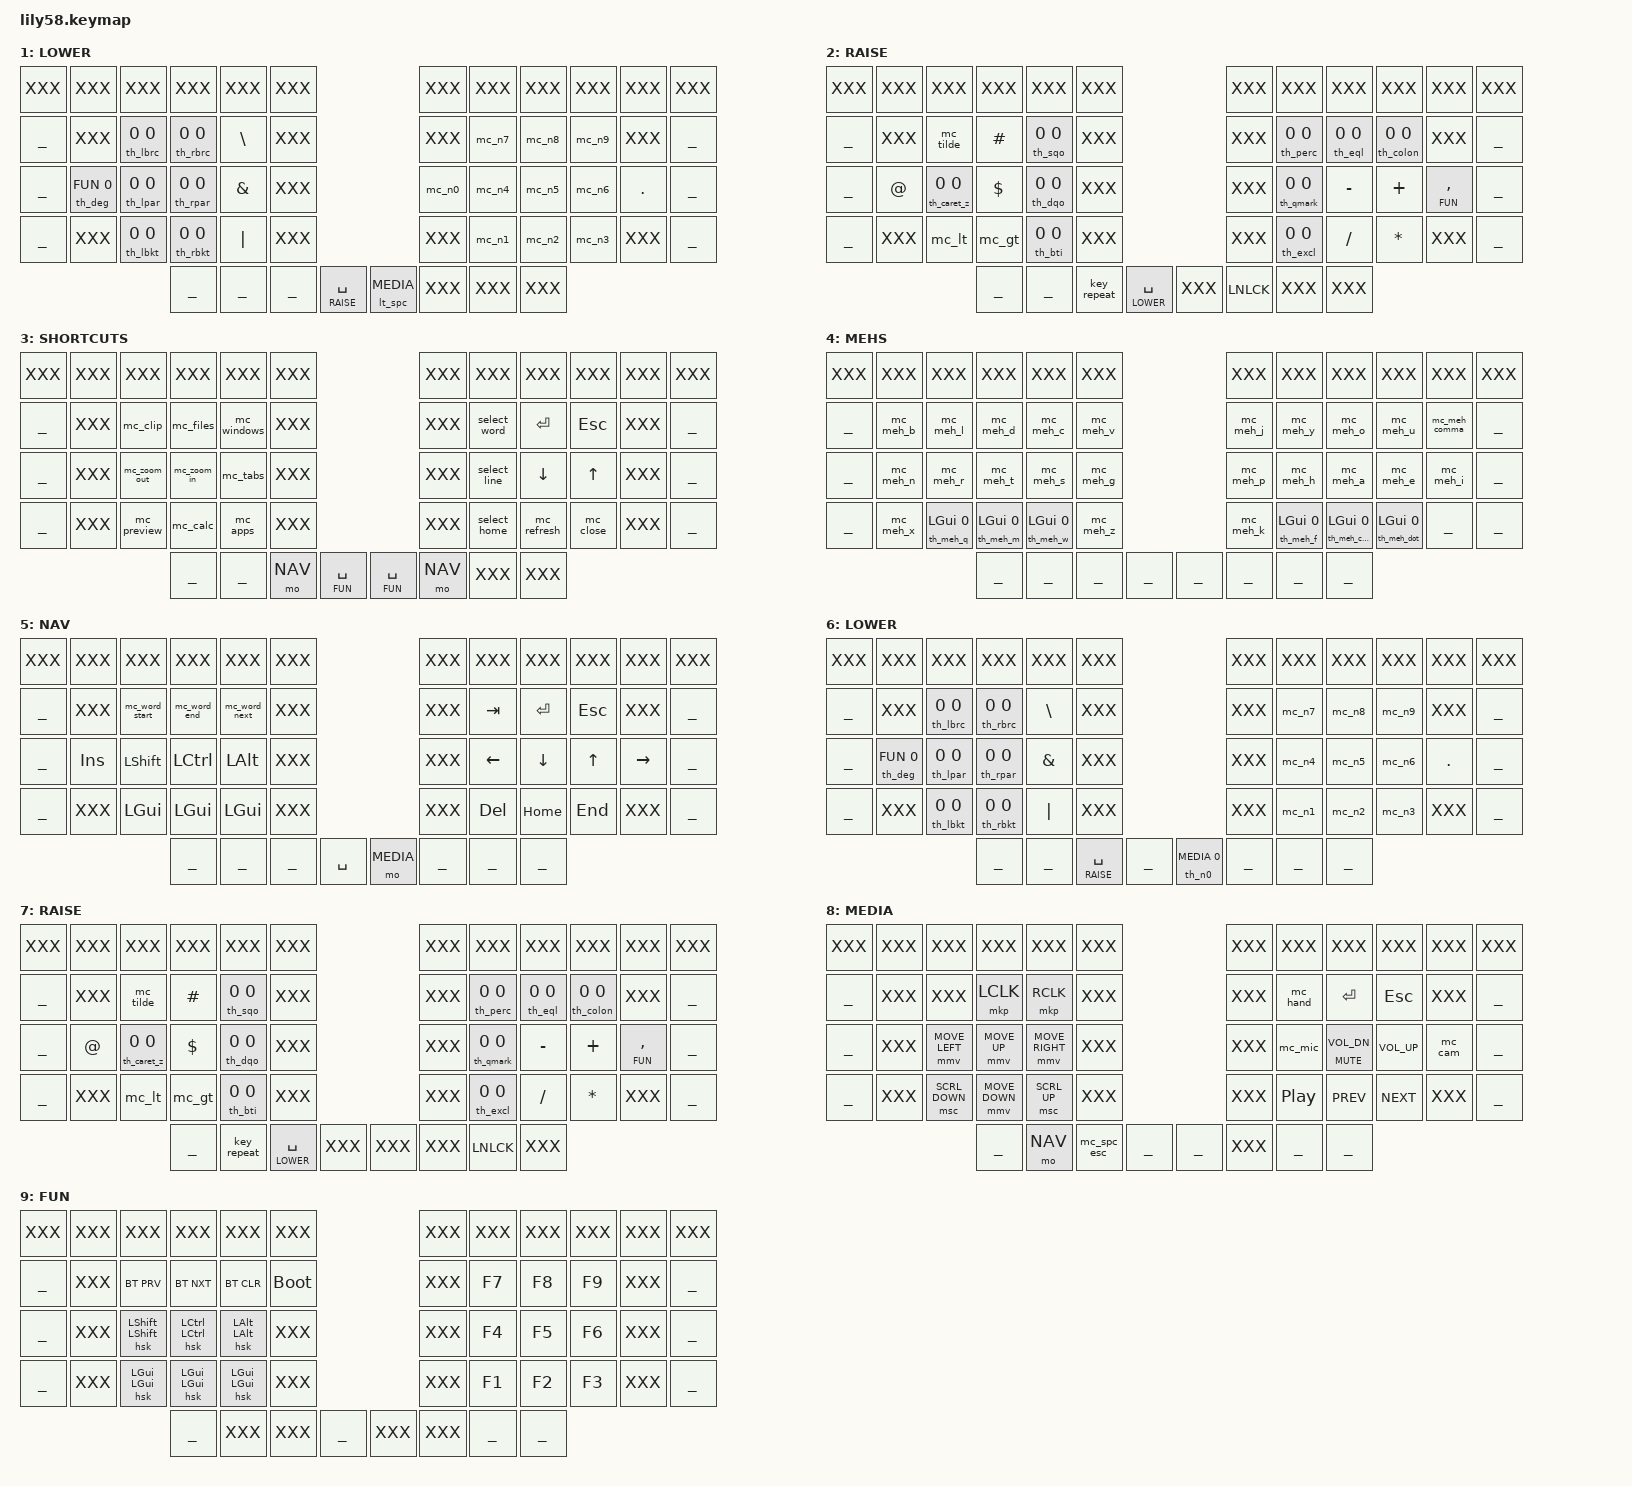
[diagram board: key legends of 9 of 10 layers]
#define CONFIG_WIRELESS
#include <behaviors.dtsi>
#include <dt-bindings/zmk/keys.h>
#include <dt-bindings/zmk/bt.h>


#include "definitions/config.dtsi"
#include "definitions/keycodes.h"

#include "zmk-helpers/helper.h"
#include "zmk-helpers/key-labels/lily58.h"

#include "features/homerow.dtsi"
#include "features/combos.dtsi"
#include "features/smart.dtsi"
// #include "features/leader.dtsi"
#include "features/mouse.dtsi"
#include "features/select.dtsi"
#include "features/symbols.dtsi"
#include "features/shortcuts.dtsi"
#include "features/magic.dtsi"


 /*                KEY POSITIONS
  ╭────────────────────────────┬────────────────────────────╮ ╭─────────────────────────────┬─────────────────────────────╮
  │  0   1   2   3   4   5     │      6   7   8   9  10  11 │ │ LT5 LT4 LT3 LT2 LT1 LT0     │     RT0 RT1 RT2 RT3 RT4 RT5 │
  │ 12  13  14  15  16  17     │     18  19  20  21  22  23 │ │ LM5 LM4 LM3 LM2 LM1 LM0     │     RM0 RM1 RM2 RM3 RM4 RM5 │
  │ 24  25  26  27  28  29     │     30  31  32  33  34  35 │ │ LB5 LB4 LB3 LB2 LB1 LB0     │     RB0 RB1 RB2 RB3 RB4 RB5 │
  │ 36  37  38  39  40  41  42 │ 43  44  45  46  47  48  49 │ │ LF5 LF4 LF3 LF2 LF1 LF0 LEC │ REC RF0 RF1 RF2 RF3 RF4 RF5 │
  ╰───────────╮ 50  51  52  53 │ 54  55  56  57 ╭───────────╯ ╰───────────╮ LH3 LH2 LH1 LH0 │ RH0 RH1 RH2 RH3 ╭───────────╯
              ╰────────────────┴────────────────╯                         ╰─────────────────┴─────────────────╯             */

/ {
  keymap {
    compatible = "zmk,keymap";
    default_layer {
      display-name = "ALPHA1";
      bindings = <

//╭───────────────────┬───────────────────┬───────────────────┬───────────────────┬───────────────────┬───────────────────╮                                         ╭───────────────────┬───────────────────┬───────────────────┬───────────────────┬───────────────────┬───────────────────╮
   XXX                 &kp N1              &kp N2              &kp N3              &kp N4              &kp N5                                                        &kp N6              &kp N7              &kp N8              &kp N9              &kp N0              XXX              
//├───────────────────┼───────────────────┼───────────────────┼───────────────────┼───────────────────┼───────────────────┤                                         ├───────────────────┼───────────────────┼───────────────────┼───────────────────┼───────────────────┼───────────────────┤
   XXX                 &kp B               &kp L               &hml LMEH D         &hml LHYP C         &kp V                                                         &kp J               &hmr RHYP Y         &hmr RMEH O         &kp U               &kp SQT             XXX
//├───────────────────┼───────────────────┼───────────────────┼───────────────────┼───────────────────┼───────────────────┤                                         ├───────────────────┼───────────────────┼───────────────────┼───────────────────┼───────────────────┼───────────────────┤
   XXX                 &lt SHORTCUTS N     &hml LSHFT R        &hml LCTRL T        &hml LALT S         &kp G                                                         &kp P               &hmr RALT H         &hmr RCTRL A        &hmr RSHFT E        &lt SHORTCUTS I     XXX
//├───────────────────┼───────────────────┼───────────────────┼───────────────────┼───────────────────┼───────────────────┼───────────────────╮ ╭───────────────────├───────────────────├───────────────────┼───────────────────┼───────────────────┼───────────────────┼───────────────────┤
   XXX                 &kp X               &hml LGUI Q         &hml LGUI M         &hml LGUI W         &kp Z               XXX                   XXX                 &kp K               &hmr RGUI F         &mm_comma           &mm_dot             &mm_qexcl           XXX
//╰───────────────────┴───────────────────┴───────────────────┴───────────────────┼───────────────────┼───────────────────┼───────────────────┤ ├───────────────────┼───────────────────┼───────────────────┴───────────────────┴───────────────────┴───────────────────┴───────────────────╯
                                                               XXX                 &key_repeat         &lt NAV BSPC        &lt LOW_CP ESC        &lt RAISE RET       &lt MEDIA SPACE     &key_repeat         XXX
//                                                            ╰───────────────────┴───────────────────┴───────────────────┴───────────────────╯ ╰───────────────────┴───────────────────┴───────────────────┴───────────────────╯
          >;
    };

    lower_layer {
         display-name = "LOWER";
         bindings = <
//╭───────────────────┬───────────────────┬───────────────────┬───────────────────┬───────────────────┬───────────────────╮                                         ╭───────────────────┬───────────────────┬───────────────────┬───────────────────┬───────────────────┬───────────────────╮
   XXX                 XXX                 XXX                 XXX                 XXX                 XXX                                                           XXX                 XXX                 XXX                 XXX                 XXX                 XXX                 
//├───────────────────┼───────────────────┼───────────────────┼───────────────────┼───────────────────┼───────────────────┤                                         ├───────────────────┼───────────────────┼───────────────────┼───────────────────┼───────────────────┼───────────────────┤
   ___                 XXX                 &th_lbrc 0 0        &th_rbrc 0 0        &kp BSLH            XXX                                                           XXX                 &mc_n7              &mc_n8              &mc_n9              XXX                 ___
//├───────────────────┼───────────────────┼───────────────────┼───────────────────┼───────────────────┼───────────────────┤                                         ├───────────────────┼───────────────────┼───────────────────┼───────────────────┼───────────────────┼───────────────────┤
   ___                 &th_deg FUN 0       &th_lpar 0 0        &th_rpar 0 0        &kp AMPS            XXX                                                           &mc_n0              &mc_n4              &mc_n5              &mc_n6              &kp DOT             ___
//├───────────────────┼───────────────────┼───────────────────┼───────────────────┼───────────────────┼───────────────────┤                                         ├───────────────────┼───────────────────┼───────────────────┼───────────────────┼───────────────────┼───────────────────┤
   ___                 XXX                 &th_lbkt 0 0        &th_rbkt 0 0        &kp PIPE            XXX                                                           XXX                 &mc_n1              &mc_n2              &mc_n3              XXX                 ___
//╰───────────────────┴───────────────────┴───────────────────┴───────────────────┼───────────────────┼───────────────────┼───────────────────┤ ├───────────────────┼───────────────────┼───────────────────┴───────────────────┴───────────────────┴───────────────────┴───────────────────╯
                                                               ___                 ___                 ___                 &lt RAISE SPACE       &lt_spc MEDIA       XXX                 XXX                 XXX
//                                                            ╰───────────────────┴───────────────────┴───────────────────┴───────────────────╯ ╰───────────────────┴───────────────────┴───────────────────┴───────────────────╯
               >;
    };
    raise_layer {
         display-name = "RAISE";
         bindings = <
//╭───────────────────┬───────────────────┬───────────────────┬───────────────────┬───────────────────┬───────────────────╮                                         ╭───────────────────┬───────────────────┬───────────────────┬───────────────────┬───────────────────┬───────────────────╮
   XXX                 XXX                 XXX                 XXX                 XXX                 XXX                                                           XXX                 XXX                 XXX                 XXX                 XXX                 XXX                 
//├───────────────────┼───────────────────┼───────────────────┼───────────────────┼───────────────────┼───────────────────┤                                         ├───────────────────┼───────────────────┼───────────────────┼───────────────────┼───────────────────┼───────────────────┤
   ___                 XXX                 &mc_tilde           &kp HASH            &th_sqo 0 0         XXX                                                           XXX                 &th_perc 0 0        &th_eql 0 0         &th_colon 0 0       XXX                 ___
//├───────────────────┼───────────────────┼───────────────────┼───────────────────┼───────────────────┼───────────────────┤                                         ├───────────────────┼───────────────────┼───────────────────┼───────────────────┼───────────────────┼───────────────────┤
   ___                 &kp AT              &th_caret_z 0 0     &kp DOLLAR          &th_dqo 0 0         XXX                                                           XXX                 &th_qmark 0 0       &kp MINUS           &kp PLUS            &lt FUN COMMA       ___
//├───────────────────┼───────────────────┼───────────────────┼───────────────────┼───────────────────┼───────────────────┤                                         ├───────────────────┼───────────────────┼───────────────────┼───────────────────┼───────────────────┼───────────────────┤
   ___                 XXX                 &mc_lt              &mc_gt              &th_bti 0 0         XXX                                                           XXX                 &th_excl 0 0        &kp SLASH           &kp STAR            XXX                 ___
//╰───────────────────┴───────────────────┴───────────────────┴───────────────────┼───────────────────┼───────────────────┼───────────────────┤ ├───────────────────┼───────────────────┼───────────────────┴───────────────────┴───────────────────┴───────────────────┴───────────────────╯
                                                               ___                 ___                 &key_repeat         &lt LOWER SPACE       XXX                 &kp LNLCK           XXX                 XXX
//                                                            ╰───────────────────┴───────────────────┴───────────────────┴───────────────────╯ ╰───────────────────┴───────────────────┴───────────────────┴───────────────────╯
               >;
    };

    shortcuts_layer {
      display-name = "SHORTCUTS";
      bindings = <

//╭───────────────────┬───────────────────┬───────────────────┬───────────────────┬───────────────────┬───────────────────╮                                         ╭───────────────────┬───────────────────┬───────────────────┬───────────────────┬───────────────────┬───────────────────╮
   XXX                 XXX                 XXX                 XXX                 XXX                 XXX                                                           XXX                 XXX                 XXX                 XXX                 XXX                 XXX                 
//├───────────────────┼───────────────────┼───────────────────┼───────────────────┼───────────────────┼───────────────────┤                                         ├───────────────────┼───────────────────┼───────────────────┼───────────────────┼───────────────────┼───────────────────┤
   ___                 XXX                 &mc_clip            &mc_files           &mc_windows         XXX                                                           XXX                 &select_word        &kp ENTER           &kp ESC             XXX                 ___
//├───────────────────┼───────────────────┼───────────────────┼───────────────────┼───────────────────┼───────────────────┤                                         ├───────────────────┼───────────────────┼───────────────────┼───────────────────┼───────────────────┼───────────────────┤
   ___                 XXX                 &mc_zoom_out        &mc_zoom_in         &mc_tabs            XXX                                                           XXX                 &select_line        &kp DOWN            &kp UP              XXX                 ___
//├───────────────────┼───────────────────┼───────────────────┼───────────────────┼───────────────────┼───────────────────┤                                         ├───────────────────┼───────────────────┼───────────────────┼───────────────────┼───────────────────┼───────────────────┤
   ___                 XXX                 &mc_preview         &mc_calc            &mc_apps            XXX                                                           XXX                 &select_home        &mc_refresh         &mc_close           XXX                 ___
//╰───────────────────┴───────────────────┴───────────────────┴───────────────────┼───────────────────┼───────────────────┼───────────────────┤ ├───────────────────┼───────────────────┼───────────────────┴───────────────────┴───────────────────┴───────────────────┴───────────────────╯
                                                               ___                 ___                 &mo NAV             &lt FUN SPACE         &lt FUN SPACE       &mo NAV             XXX                 XXX
//                                                            ╰───────────────────┴───────────────────┴───────────────────┴───────────────────╯ ╰───────────────────┴───────────────────┴───────────────────┴───────────────────╯
               >;
    };

    mehs_layer {
         display-name = "MEHS";
         bindings = <
//╭───────────────────┬───────────────────┬───────────────────┬───────────────────┬───────────────────┬───────────────────╮                                         ╭───────────────────┬───────────────────┬───────────────────┬───────────────────┬───────────────────┬───────────────────╮
   XXX                 XXX                 XXX                 XXX                 XXX                 XXX                                                           XXX                 XXX                 XXX                 XXX                 XXX                 XXX                 
//├───────────────────┼───────────────────┼───────────────────┼───────────────────┼───────────────────┼───────────────────┤                                         ├───────────────────┼───────────────────┼───────────────────┼───────────────────┼───────────────────┼───────────────────┤
   ___                 &mc_meh_b           &mc_meh_l           &mc_meh_d           &mc_meh_c           &mc_meh_v                                                     &mc_meh_j           &mc_meh_y           &mc_meh_o           &mc_meh_u           &mc_meh_comma        ___
//├───────────────────┼───────────────────┼───────────────────┼───────────────────┼───────────────────┼───────────────────┤                                         ├───────────────────┼───────────────────┼───────────────────┼───────────────────┼───────────────────┼───────────────────┤
   ___                 &mc_meh_n           &mc_meh_r           &mc_meh_t           &mc_meh_s           &mc_meh_g                                                     &mc_meh_p           &mc_meh_h           &mc_meh_a           &mc_meh_e           &mc_meh_i           ___
//├───────────────────┼───────────────────┼───────────────────┼───────────────────┼───────────────────┼───────────────────┤                                         ├───────────────────┼───────────────────┼───────────────────┼───────────────────┼───────────────────┼───────────────────┤
   ___                 &mc_meh_x           &th_meh_q LGUI 0    &th_meh_m LGUI 0    &th_meh_w LGUI 0    &mc_meh_z                                                     &mc_meh_k           &th_meh_f LGUI 0    &th_meh_comm LGUI 0 &th_meh_dot LGUI 0  ___                 ___
//╰───────────────────┴───────────────────┴───────────────────┴───────────────────┼───────────────────┼───────────────────┼───────────────────┤ ├───────────────────┼───────────────────┼───────────────────┴───────────────────┴───────────────────┴───────────────────┴───────────────────╯
                                                               ___                 ___                 ___                 ___                   ___                 ___                 ___                 ___
//                                                            ╰───────────────────┴───────────────────┴───────────────────┴───────────────────╯ ╰───────────────────┴───────────────────┴───────────────────┴───────────────────╯
          >;
    };

    navigation_layer {
         display-name = "NAV";
         bindings = <

//╭───────────────────┬───────────────────┬───────────────────┬───────────────────┬───────────────────┬───────────────────╮                                         ╭───────────────────┬───────────────────┬───────────────────┬───────────────────┬───────────────────┬───────────────────╮
   XXX                 XXX                 XXX                 XXX                 XXX                 XXX                                                           XXX                 XXX                 XXX                 XXX                 XXX                 XXX                 
//├───────────────────┼───────────────────┼───────────────────┼───────────────────┼───────────────────┼───────────────────┤                                         ├───────────────────┼───────────────────┼───────────────────┼───────────────────┼───────────────────┼───────────────────┤
   ___                 XXX                 &mc_word_start      &mc_word_end        &mc_word_next       XXX                                                           XXX                 &kp TAB             &kp ENTER           &kp ESC             XXX                 ___
//├───────────────────┼───────────────────┼───────────────────┼───────────────────┼───────────────────┼───────────────────┤                                         ├───────────────────┼───────────────────┼───────────────────┼───────────────────┼───────────────────┼───────────────────┤
   ___                 &kp INS             &kp LSHFT           &kp LCTRL           &kp LALT            XXX                                                           XXX                 &kp LEFT            &kp DOWN            &kp UP              &kp RIGHT           ___
//├───────────────────┼───────────────────┼───────────────────┼───────────────────┼───────────────────┼───────────────────┤                                         ├───────────────────┼───────────────────┼───────────────────┼───────────────────┼───────────────────┼───────────────────┤
   ___                 XXX                 &kp LGUI            &kp LGUI            &kp LGUI            XXX                                                           XXX                 &kp DEL             &kp HOME            &kp END             XXX                 ___
//╰───────────────────┴───────────────────┴───────────────────┴───────────────────┼───────────────────┼───────────────────┼───────────────────┤ ├───────────────────┼───────────────────┼───────────────────┴───────────────────┴───────────────────┴───────────────────┴───────────────────╯
                                                               ___                 ___                 ___                 &kp SPACE             &mo MEDIA           ___                 ___                 ___
//                                                            ╰───────────────────┴───────────────────┴───────────────────┴───────────────────╯ ╰───────────────────┴───────────────────┴───────────────────┴───────────────────╯
          >;
    };
    lower_copy_layer {
         display-name = "LOWER";
         bindings = <
//╭───────────────────┬───────────────────┬───────────────────┬───────────────────┬───────────────────┬───────────────────╮                                         ╭───────────────────┬───────────────────┬───────────────────┬───────────────────┬───────────────────┬───────────────────╮
   XXX                 XXX                 XXX                 XXX                 XXX                 XXX                                                           XXX                 XXX                 XXX                 XXX                 XXX                 XXX                 
//├───────────────────┼───────────────────┼───────────────────┼───────────────────┼───────────────────┼───────────────────┤                                         ├───────────────────┼───────────────────┼───────────────────┼───────────────────┼───────────────────┼───────────────────┤
   ___                 XXX                 &th_lbrc 0 0        &th_rbrc 0 0        &kp BSLH            XXX                                                           XXX                 &mc_n7              &mc_n8              &mc_n9              XXX                 ___
//├───────────────────┼───────────────────┼───────────────────┼───────────────────┼───────────────────┼───────────────────┤                                         ├───────────────────┼───────────────────┼───────────────────┼───────────────────┼───────────────────┼───────────────────┤
   ___                 &th_deg FUN 0       &th_lpar 0 0        &th_rpar 0 0        &kp AMPS            XXX                                                           XXX                 &mc_n4              &mc_n5              &mc_n6              &kp DOT             ___
//├───────────────────┼───────────────────┼───────────────────┼───────────────────┼───────────────────┼───────────────────┤                                         ├───────────────────┼───────────────────┼───────────────────┼───────────────────┼───────────────────┼───────────────────┤
   ___                 XXX                 &th_lbkt 0 0        &th_rbkt 0 0        &kp PIPE            XXX                                                           XXX                 &mc_n1              &mc_n2              &mc_n3              XXX                 ___
//╰───────────────────┴───────────────────┴───────────────────┴───────────────────┼───────────────────┼───────────────────┼───────────────────┤ ├───────────────────┼───────────────────┼───────────────────┴───────────────────┴───────────────────┴───────────────────┴───────────────────╯
                                                               ___                 ___                 &lt RAISE SPACE     ___                   &th_n0 MEDIA 0      ___                 ___                 ___
//                                                            ╰───────────────────┴───────────────────┴───────────────────┴───────────────────╯ ╰───────────────────┴───────────────────┴───────────────────┴───────────────────╯
               >;
    };
    raise_copy_layer {
         display-name = "RAISE";
         bindings = <
//╭───────────────────┬───────────────────┬───────────────────┬───────────────────┬───────────────────┬───────────────────╮                                         ╭───────────────────┬───────────────────┬───────────────────┬───────────────────┬───────────────────┬───────────────────╮
   XXX                 XXX                 XXX                 XXX                 XXX                 XXX                                                           XXX                 XXX                 XXX                 XXX                 XXX                 XXX                 
//├───────────────────┼───────────────────┼───────────────────┼───────────────────┼───────────────────┼───────────────────┤                                         ├───────────────────┼───────────────────┼───────────────────┼───────────────────┼───────────────────┼───────────────────┤
   ___                 XXX                 &mc_tilde           &kp HASH            &th_sqo 0 0         XXX                                                           XXX                 &th_perc 0 0        &th_eql 0 0         &th_colon 0 0       XXX                 ___
//├───────────────────┼───────────────────┼───────────────────┼───────────────────┼───────────────────┼───────────────────┤                                         ├───────────────────┼───────────────────┼───────────────────┼───────────────────┼───────────────────┼───────────────────┤
   ___                 &kp AT              &th_caret_z 0 0     &kp DOLLAR          &th_dqo 0 0         XXX                                                           XXX                 &th_qmark 0 0       &kp MINUS           &kp PLUS            &lt FUN COMMA       ___
//├───────────────────┼───────────────────┼───────────────────┼───────────────────┼───────────────────┼───────────────────┤                                         ├───────────────────┼───────────────────┼───────────────────┼───────────────────┼───────────────────┼───────────────────┤
   ___                 XXX                 &mc_lt              &mc_gt              &th_bti 0 0         XXX                                                           XXX                 &th_excl 0 0        &kp SLASH           &kp STAR            XXX                 ___
//╰───────────────────┴───────────────────┴───────────────────┴───────────────────┼───────────────────┼───────────────────┼───────────────────┤ ├───────────────────┼───────────────────┼───────────────────┴───────────────────┴───────────────────┴───────────────────┴───────────────────╯
                                                               ___                 &key_repeat         &lt LOWER SPACE     XXX                   XXX                 XXX                 &kp LNLCK           XXX
//                                                            ╰───────────────────┴───────────────────┴───────────────────┴───────────────────╯ ╰───────────────────┴───────────────────┴───────────────────┴───────────────────╯
               >;
    };

    media_layer {
        display-name = "MEDIA";
        bindings = <

//╭───────────────────┬───────────────────┬───────────────────┬───────────────────┬───────────────────┬───────────────────╮                                         ╭───────────────────┬───────────────────┬───────────────────┬───────────────────┬───────────────────┬───────────────────╮
   XXX                 XXX                 XXX                 XXX                 XXX                 XXX                                                           XXX                 XXX                 XXX                 XXX                 XXX                 XXX                 
//├───────────────────┼───────────────────┼───────────────────┼───────────────────┼───────────────────┼───────────────────┤                                         ├───────────────────┼───────────────────┼───────────────────┼───────────────────┼───────────────────┼───────────────────┤
   ___                 XXX                 XXX                 &mkp LCLK           &mkp RCLK           XXX                                                           XXX                 &mc_hand            &kp ENTER           &kp ESC             XXX                 ___
//├───────────────────┼───────────────────┼───────────────────┼───────────────────┼───────────────────┼───────────────────┤                                         ├───────────────────┼───────────────────┼───────────────────┼───────────────────┼───────────────────┼───────────────────┤
   ___                 XXX                 &mmv MOVE_LEFT      &mmv MOVE_UP        &mmv MOVE_RIGHT     XXX                                                           XXX                 &mc_mic             &mt C_MUTE C_VOL_DN &kp C_VOL_UP        &mc_cam             ___
//├───────────────────┼───────────────────┼───────────────────┼───────────────────┼───────────────────┼───────────────────┤                                         ├───────────────────┼───────────────────┼───────────────────┼───────────────────┼───────────────────┼───────────────────┤
   ___                 XXX                 &msc SCRL_DOWN      &mmv MOVE_DOWN      &msc SCRL_UP        XXX                                                           XXX                 &kp C_PP            &kp C_PREV          &kp C_NEXT          XXX                 ___
//╰───────────────────┴───────────────────┴───────────────────┴───────────────────┼───────────────────┼───────────────────┼───────────────────┤ ├───────────────────┼───────────────────┼───────────────────┴───────────────────┴───────────────────┴───────────────────┴───────────────────╯
                                                               ___                 &mo NAV             &mc_spc_esc           ___                 ___                 XXX                 ___                 ___ 
//                                                            ╰───────────────────┴───────────────────┴───────────────────┴───────────────────╯ ╰───────────────────┴───────────────────┴───────────────────┴───────────────────╯
               >;
    };

    functions_layer {
         display-name = "FUN";
         bindings = <
//╭───────────────────┬───────────────────┬───────────────────┬───────────────────┬───────────────────┬───────────────────╮                                         ╭───────────────────┬───────────────────┬───────────────────┬───────────────────┬───────────────────┬───────────────────╮
   XXX                 XXX                 XXX                 XXX                 XXX                 XXX                                                           XXX                 XXX                 XXX                 XXX                 XXX                 XXX                 
//├───────────────────┼───────────────────┼───────────────────┼───────────────────┼───────────────────┼───────────────────┤                                         ├───────────────────┼───────────────────┼───────────────────┼───────────────────┼───────────────────┼───────────────────┤
   ___                 XXX                 &bt BT_PRV          &bt BT_NXT          &bt BT_CLR          &bootloader                                                   XXX                 &kp F7              &kp F8              &kp F9              XXX                 ___
//├───────────────────┼───────────────────┼───────────────────┼───────────────────┼───────────────────┼───────────────────┤                                         ├───────────────────┼───────────────────┼───────────────────┼───────────────────┼───────────────────┼───────────────────┤
   ___                 XXX                 &hsk LSHFT LSHFT    &hsk LCTRL LCTRL    &hsk LALT LALT      XXX                                                           XXX                 &kp F4              &kp F5              &kp F6              XXX                 ___
//├───────────────────┼───────────────────┼───────────────────┼───────────────────┼───────────────────┼───────────────────┤                                         ├───────────────────┼───────────────────┼───────────────────┼───────────────────┼───────────────────┼───────────────────┤
   ___                 XXX                 &hsk LGUI LGUI      &hsk LGUI LGUI      &hsk LGUI LGUI      XXX                                                           XXX                 &kp F1              &kp F2              &kp F3              XXX                 ___
//╰───────────────────┴───────────────────┴───────────────────┴───────────────────┼───────────────────┼───────────────────┼───────────────────┤ ├───────────────────┼───────────────────┼───────────────────┴───────────────────┴───────────────────┴───────────────────┴───────────────────╯
                                                               ___                 XXX                 XXX                 ___                   XXX                 XXX                 ___                 ___
//                                                            ╰───────────────────┴───────────────────┴───────────────────┴───────────────────╯ ╰───────────────────┴───────────────────┴───────────────────┴───────────────────╯
          >;
    };
  };
};
